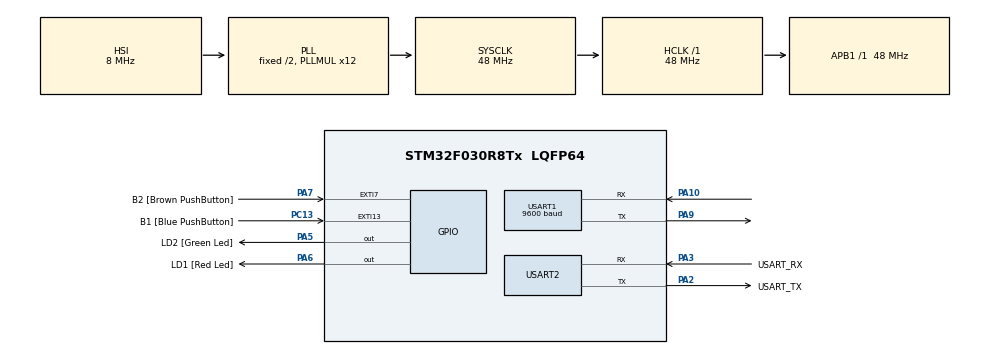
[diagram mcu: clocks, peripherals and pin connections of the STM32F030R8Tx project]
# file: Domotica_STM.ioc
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FREERTOS.INCLUDE_uxTaskGetStackHighWaterMark=1
FREERTOS.Tasks01=defaultTask,0,128,StartDefaultTask,Default,NULL
FREERTOS.configCHECK_FOR_STACK_OVERFLOW=2
Mcu.Family=STM32F0
Mcu.Name=STM32F030R8Tx
Mcu.Package=LQFP64
NVIC.TIM6_IRQn=true\:0\:0\:false\:false\:true\:false\:false
NVIC.TimeBase=TIM6_IRQn
NVIC.TimeBaseIP=TIM6
NVIC.USART1_IRQn=true\:3\:0\:false\:false\:true\:true\:true
PA10.Mode=Asynchronous
PA10.Signal=USART1_RX
PA13.GPIO_Label=TMS
PA13.Mode=Serial_Wire
PA13.Signal=SYS_SWDIO
PA14.GPIO_Label=TCK
PA14.Mode=Serial_Wire
PA14.Signal=SYS_SWCLK
PA2.GPIO_Label=USART_TX
PA2.GPIO_Mode=GPIO_MODE_AF_PP
PA2.GPIO_PuPd=GPIO_NOPULL
PA2.GPIO_Speed=GPIO_SPEED_FREQ_LOW
PA2.Mode=Asynchronous
PA2.Signal=USART2_TX
PA3.GPIO_Label=USART_RX
PA3.GPIO_Mode=GPIO_MODE_AF_PP
PA3.GPIO_PuPd=GPIO_NOPULL
PA3.GPIO_Speed=GPIO_SPEED_FREQ_LOW
PA3.Mode=Asynchronous
PA3.Signal=USART2_RX
PA5.GPIO_Label=LD2 [Green Led]
PA5.GPIO_Mode=GPIO_MODE_OUTPUT_PP
PA5.GPIO_PuPd=GPIO_NOPULL
PA5.GPIO_Speed=GPIO_SPEED_FREQ_LOW
PA5.Signal=GPIO_Output
PA6.GPIO_Label=LD1 [Red Led]
PA6.Signal=GPIO_Output
PA7.GPIO_Label=B2 [Brown PushButton]
PA7.GPIO_ModeDefaultEXTI=GPIO_MODE_IT_RISING
PA7.Signal=GPXTI7
PA9.Mode=Asynchronous
PA9.Signal=USART1_TX
PC13.GPIO_Label=B1 [Blue PushButton]
PC13.GPIO_ModeDefaultEXTI=GPIO_MODE_IT_FALLING
PC13.Signal=GPXTI13
PC14-OSC32_IN.Mode=LSE-External-Oscillator
PC14-OSC32_IN.Signal=RCC_OSC32_IN
PC15-OSC32_OUT.Mode=LSE-External-Oscillator
PC15-OSC32_OUT.Signal=RCC_OSC32_OUT
PF0-OSC_IN.Mode=HSE-External-Clock-Source
PF0-OSC_IN.Signal=RCC_OSC_IN
PF1-OSC_OUT.Signal=RCC_OSC_OUT
ProjectManager.HeapSize=0x200
ProjectManager.StackSize=0x400
ProjectManager.TargetToolchain=SW4STM32
RCC.AHBFreq_Value=48000000
RCC.APB1Freq_Value=48000000
RCC.APB1TimFreq_Value=48000000
RCC.HCLKFreq_Value=48000000
RCC.PLLMUL=RCC_PLL_MUL12
RCC.SYSCLKFreq_VALUE=48000000
RCC.SYSCLKSource=RCC_SYSCLKSOURCE_PLLCLK
USART1.BaudRate=9600
USART1.VirtualMode-Asynchronous=VM_ASYNC
USART2.VirtualMode-Asynchronous=VM_ASYNC
VP_FREERTOS_VS_ENABLE.Mode=Enabled
VP_SYS_VS_tim6.Mode=TIM6
board=NUCLEO-F030R8

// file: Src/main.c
/* USER CODE BEGIN Header */
/**
  ******************************************************************************
  * @file           : main.c
  * @brief          : Main program body
  ******************************************************************************
  * This notice applies to any and all portions of this file
  * that are not between comment pairs USER CODE BEGIN and
  * USER CODE END. Other portions of this file, whether
  * inserted by the user or by software development tools
  * are owned by their respective copyright owners.
  *
  * Copyright (c) 2019 STMicroelectronics International N.V.
  * All rights reserved.
  *
  * Redistribution and use in source and binary forms, with or without
  * modification, are permitted, provided that the following conditions are met:
  *
  * 1. Redistribution of source code must retain the above copyright notice,
  *    this list of conditions and the following disclaimer.
  * 2. Redistributions in binary form must reproduce the above copyright notice,
  *    this list of conditions and the following disclaimer in the documentation
  *    and/or other materials provided with the distribution.
  * 3. Neither the name of STMicroelectronics nor the names of other
  *    contributors to this software may be used to endorse or promote products
  *    derived from this software without specific written permission.
  * 4. This software, including modifications and/or derivative works of this
  *    software, must execute solely and exclusively on microcontroller or
  *    microprocessor devices manufactured by or for STMicroelectronics.
  * 5. Redistribution and use of this software other than as permitted under
  *    this license is void and will automatically terminate your rights under
  *    this license.
  *
  * THIS SOFTWARE IS PROVIDED BY STMICROELECTRONICS AND CONTRIBUTORS "AS IS"
  * AND ANY EXPRESS, IMPLIED OR STATUTORY WARRANTIES, INCLUDING, BUT NOT
  * LIMITED TO, THE IMPLIED WARRANTIES OF MERCHANTABILITY, FITNESS FOR A
  * PARTICULAR PURPOSE AND NON-INFRINGEMENT OF THIRD PARTY INTELLECTUAL PROPERTY
  * RIGHTS ARE DISCLAIMED TO THE FULLEST EXTENT PERMITTED BY LAW. IN NO EVENT
  * SHALL STMICROELECTRONICS OR CONTRIBUTORS BE LIABLE FOR ANY DIRECT, INDIRECT,
  * INCIDENTAL, SPECIAL, EXEMPLARY, OR CONSEQUENTIAL DAMAGES (INCLUDING, BUT NOT
  * LIMITED TO, PROCUREMENT OF SUBSTITUTE GOODS OR SERVICES; LOSS OF USE, DATA,
  * OR PROFITS; OR BUSINESS INTERRUPTION) HOWEVER CAUSED AND ON ANY THEORY OF
  * LIABILITY, WHETHER IN CONTRACT, STRICT LIABILITY, OR TORT (INCLUDING
  * NEGLIGENCE OR OTHERWISE) ARISING IN ANY WAY OUT OF THE USE OF THIS SOFTWARE,
  * EVEN IF ADVISED OF THE POSSIBILITY OF SUCH DAMAGE.
  *
  ******************************************************************************
  */
/* USER CODE END Header */

#include "main.h"
#include "cmsis_os.h"

/* USER CODE BEGIN Includes */
#include "xbee.h"
/* USER CODE END Includes */

osThreadId defaultTaskHandle;
/* USER CODE BEGIN PV */
/* Private variables ---------------------------------------------------------*/

/* USER CODE END PV */

void SystemClock_Config(void);
static void MX_GPIO_Init(void);
static void MX_USART2_UART_Init(void);
static void MX_USART1_UART_Init(void);
void StartDefaultTask(void const * argument);

/* USER CODE BEGIN PFP */
/* Private function prototypes -----------------------------------------------*/
/* USER CODE END PFP */

/* USER CODE BEGIN 0 */
void vApplicationStackOverflowHook( TaskHandle_t xTask, char *pcTaskName )
  {
	  while(1);
  }
/* USER CODE END 0 */

int main(void)
{

  /* MCU Configuration--------------------------------------------------------*/

  /* Reset of all peripherals, Initializes the Flash interface and the Systick. */
  HAL_Init();

  /* Configure the system clock */
  SystemClock_Config();

  /* Initialize all configured peripherals */
  MX_GPIO_Init();
  MX_USART2_UART_Init();
  MX_USART1_UART_Init();
  /* USER CODE BEGIN 2 */

  xTaskCreate( xbeeConfigTask,
		  	  (char *) "XbeeConfig",
			  configMINIMAL_STACK_SIZE,
			  NULL,
			  2,
			  NULL
		  );

  /* USER CODE END 2 */

  /* Create the thread(s) */
  /* definition and creation of defaultTask */
  osThreadDef(defaultTask, StartDefaultTask, osPriorityNormal, 0, 128);
  defaultTaskHandle = osThreadCreate(osThread(defaultTask), NULL);

  /* Start scheduler */
  osKernelStart();

  /* We should never get here as control is now taken by the scheduler */

  /* Infinite loop */
  while (1)
  {

  }
}

void SystemClock_Config(void)
{
  RCC_OscInitTypeDef RCC_OscInitStruct = {0};
  RCC_ClkInitTypeDef RCC_ClkInitStruct = {0};
  RCC_PeriphCLKInitTypeDef PeriphClkInit = {0};

  /**Initializes the CPU, AHB and APB busses clocks
  */
  RCC_OscInitStruct.OscillatorType = RCC_OSCILLATORTYPE_HSI;
  RCC_OscInitStruct.HSIState = RCC_HSI_ON;
  RCC_OscInitStruct.HSICalibrationValue = RCC_HSICALIBRATION_DEFAULT;
  RCC_OscInitStruct.PLL.PLLState = RCC_PLL_ON;
  RCC_OscInitStruct.PLL.PLLSource = RCC_PLLSOURCE_HSI;
  RCC_OscInitStruct.PLL.PLLMUL = RCC_PLL_MUL12;
  RCC_OscInitStruct.PLL.PREDIV = RCC_PREDIV_DIV1;
  if (HAL_RCC_OscConfig(&RCC_OscInitStruct) != HAL_OK)
  {
    Error_Handler();
  }
  /**Initializes the CPU, AHB and APB busses clocks
  */
  RCC_ClkInitStruct.ClockType = RCC_CLOCKTYPE_HCLK|RCC_CLOCKTYPE_SYSCLK
                              |RCC_CLOCKTYPE_PCLK1;
  RCC_ClkInitStruct.SYSCLKSource = RCC_SYSCLKSOURCE_PLLCLK;
  RCC_ClkInitStruct.AHBCLKDivider = RCC_SYSCLK_DIV1;
  RCC_ClkInitStruct.APB1CLKDivider = RCC_HCLK_DIV1;

  if (HAL_RCC_ClockConfig(&RCC_ClkInitStruct, FLASH_LATENCY_1) != HAL_OK)
  {
    Error_Handler();
  }
  PeriphClkInit.PeriphClockSelection = RCC_PERIPHCLK_USART1;
  PeriphClkInit.Usart1ClockSelection = RCC_USART1CLKSOURCE_PCLK1;
  if (HAL_RCCEx_PeriphCLKConfig(&PeriphClkInit) != HAL_OK)
  {
    Error_Handler();
  }
}

static void MX_USART1_UART_Init(void)
{

  LL_USART_InitTypeDef USART_InitStruct = {0};

  LL_GPIO_InitTypeDef GPIO_InitStruct = {0};

  /* Peripheral clock enable */
  LL_APB1_GRP2_EnableClock(LL_APB1_GRP2_PERIPH_USART1);

  LL_AHB1_GRP1_EnableClock(LL_AHB1_GRP1_PERIPH_GPIOA);
  /**USART1 GPIO Configuration
  PA9   ------> USART1_TX
  PA10   ------> USART1_RX
  */
  GPIO_InitStruct.Pin = LL_GPIO_PIN_9;
  GPIO_InitStruct.Mode = LL_GPIO_MODE_ALTERNATE;
  GPIO_InitStruct.Speed = LL_GPIO_SPEED_FREQ_HIGH;
  GPIO_InitStruct.OutputType = LL_GPIO_OUTPUT_PUSHPULL;
  GPIO_InitStruct.Pull = LL_GPIO_PULL_NO;
  GPIO_InitStruct.Alternate = LL_GPIO_AF_1;
  LL_GPIO_Init(GPIOA, &GPIO_InitStruct);

  GPIO_InitStruct.Pin = LL_GPIO_PIN_10;
  GPIO_InitStruct.Mode = LL_GPIO_MODE_ALTERNATE;
  GPIO_InitStruct.Speed = LL_GPIO_SPEED_FREQ_HIGH;
  GPIO_InitStruct.OutputType = LL_GPIO_OUTPUT_PUSHPULL;
  GPIO_InitStruct.Pull = LL_GPIO_PULL_NO;
  GPIO_InitStruct.Alternate = LL_GPIO_AF_1;
  LL_GPIO_Init(GPIOA, &GPIO_InitStruct);

  /* USART1 interrupt Init */
  NVIC_SetPriority(USART1_IRQn, 3);
  NVIC_EnableIRQ(USART1_IRQn);

  USART_InitStruct.BaudRate = 9600;
  USART_InitStruct.DataWidth = LL_USART_DATAWIDTH_8B;
  USART_InitStruct.StopBits = LL_USART_STOPBITS_1;
  USART_InitStruct.Parity = LL_USART_PARITY_NONE;
  USART_InitStruct.TransferDirection = LL_USART_DIRECTION_TX_RX;
  USART_InitStruct.HardwareFlowControl = LL_USART_HWCONTROL_NONE;
  USART_InitStruct.OverSampling = LL_USART_OVERSAMPLING_16;
  LL_USART_Init(USART1, &USART_InitStruct);
  LL_USART_DisableIT_CTS(USART1);
  LL_USART_DisableOverrunDetect(USART1);
  LL_USART_ConfigAsyncMode(USART1);
  LL_USART_Enable(USART1);

}

static void MX_USART2_UART_Init(void)
{

  LL_USART_InitTypeDef USART_InitStruct = {0};

  LL_GPIO_InitTypeDef GPIO_InitStruct = {0};

  /* Peripheral clock enable */
  LL_APB1_GRP1_EnableClock(LL_APB1_GRP1_PERIPH_USART2);

  LL_AHB1_GRP1_EnableClock(LL_AHB1_GRP1_PERIPH_GPIOA);
  /**USART2 GPIO Configuration
  PA2   ------> USART2_TX
  PA3   ------> USART2_RX
  */
  GPIO_InitStruct.Pin = LL_GPIO_PIN_2;
  GPIO_InitStruct.Mode = LL_GPIO_MODE_ALTERNATE;
  GPIO_InitStruct.Speed = LL_GPIO_SPEED_FREQ_LOW;
  GPIO_InitStruct.OutputType = LL_GPIO_OUTPUT_PUSHPULL;
  GPIO_InitStruct.Pull = LL_GPIO_PULL_NO;
  GPIO_InitStruct.Alternate = LL_GPIO_AF_1;
  LL_GPIO_Init(GPIOA, &GPIO_InitStruct);

  GPIO_InitStruct.Pin = LL_GPIO_PIN_3;
  GPIO_InitStruct.Mode = LL_GPIO_MODE_ALTERNATE;
  GPIO_InitStruct.Speed = LL_GPIO_SPEED_FREQ_LOW;
  GPIO_InitStruct.OutputType = LL_GPIO_OUTPUT_PUSHPULL;
  GPIO_InitStruct.Pull = LL_GPIO_PULL_NO;
  GPIO_InitStruct.Alternate = LL_GPIO_AF_1;
  LL_GPIO_Init(GPIOA, &GPIO_InitStruct);

  USART_InitStruct.BaudRate = 38400;
  USART_InitStruct.DataWidth = LL_USART_DATAWIDTH_8B;
  USART_InitStruct.StopBits = LL_USART_STOPBITS_1;
  USART_InitStruct.Parity = LL_USART_PARITY_NONE;
  USART_InitStruct.TransferDirection = LL_USART_DIRECTION_TX_RX;
  USART_InitStruct.HardwareFlowControl = LL_USART_HWCONTROL_NONE;
  USART_InitStruct.OverSampling = LL_USART_OVERSAMPLING_16;
  LL_USART_Init(USART2, &USART_InitStruct);
  LL_USART_DisableIT_CTS(USART2);
  LL_USART_DisableOverrunDetect(USART2);
  LL_USART_ConfigAsyncMode(USART2);
  LL_USART_Enable(USART2);

}

static void MX_GPIO_Init(void)
{
  GPIO_InitTypeDef GPIO_InitStruct = {0};

  /* GPIO Ports Clock Enable */
  __HAL_RCC_GPIOC_CLK_ENABLE();
  __HAL_RCC_GPIOF_CLK_ENABLE();
  __HAL_RCC_GPIOA_CLK_ENABLE();
  __HAL_RCC_GPIOB_CLK_ENABLE();
  __HAL_RCC_GPIOD_CLK_ENABLE();

  /*Configure GPIO pin Output Level */
  HAL_GPIO_WritePin(GPIOA, LD2_Pin|LD1_Pin, GPIO_PIN_RESET);

  /*Configure GPIO pin : B1_Pin */
  GPIO_InitStruct.Pin = B1_Pin;
  GPIO_InitStruct.Mode = GPIO_MODE_IT_FALLING;
  GPIO_InitStruct.Pull = GPIO_NOPULL;
  HAL_GPIO_Init(B1_GPIO_Port, &GPIO_InitStruct);

  /*Configure GPIO pins : PC0 PC1 PC2 PC3
                           PC4 PC5 PC6 PC7
                           PC8 PC9 PC10 PC11
                           PC12 */
  GPIO_InitStruct.Pin = GPIO_PIN_0|GPIO_PIN_1|GPIO_PIN_2|GPIO_PIN_3
                          |GPIO_PIN_4|GPIO_PIN_5|GPIO_PIN_6|GPIO_PIN_7
                          |GPIO_PIN_8|GPIO_PIN_9|GPIO_PIN_10|GPIO_PIN_11
                          |GPIO_PIN_12;
  GPIO_InitStruct.Mode = GPIO_MODE_ANALOG;
  GPIO_InitStruct.Pull = GPIO_NOPULL;
  HAL_GPIO_Init(GPIOC, &GPIO_InitStruct);

  /*Configure GPIO pins : PA0 PA1 PA4 PA8
                           PA11 PA12 PA15 */
  GPIO_InitStruct.Pin = GPIO_PIN_0|GPIO_PIN_1|GPIO_PIN_4|GPIO_PIN_8
                          |GPIO_PIN_11|GPIO_PIN_12|GPIO_PIN_15;
  GPIO_InitStruct.Mode = GPIO_MODE_ANALOG;
  GPIO_InitStruct.Pull = GPIO_NOPULL;
  HAL_GPIO_Init(GPIOA, &GPIO_InitStruct);

  /*Configure GPIO pins : PF4 PF5 PF6 PF7 */
  GPIO_InitStruct.Pin = GPIO_PIN_4|GPIO_PIN_5|GPIO_PIN_6|GPIO_PIN_7;
  GPIO_InitStruct.Mode = GPIO_MODE_ANALOG;
  GPIO_InitStruct.Pull = GPIO_NOPULL;
  HAL_GPIO_Init(GPIOF, &GPIO_InitStruct);

  /*Configure GPIO pins : LD2_Pin LD1_Pin */
  GPIO_InitStruct.Pin = LD2_Pin|LD1_Pin;
  GPIO_InitStruct.Mode = GPIO_MODE_OUTPUT_PP;
  GPIO_InitStruct.Pull = GPIO_NOPULL;
  GPIO_InitStruct.Speed = GPIO_SPEED_FREQ_LOW;
  HAL_GPIO_Init(GPIOA, &GPIO_InitStruct);

  /*Configure GPIO pin : B2_Pin */
  GPIO_InitStruct.Pin = B2_Pin;
  GPIO_InitStruct.Mode = GPIO_MODE_IT_RISING;
  GPIO_InitStruct.Pull = GPIO_NOPULL;
  HAL_GPIO_Init(B2_GPIO_Port, &GPIO_InitStruct);

  /*Configure GPIO pins : PB0 PB1 PB2 PB10
                           PB11 PB12 PB13 PB14
                           PB15 PB3 PB4 PB5
                           PB6 PB7 PB8 PB9 */
  GPIO_InitStruct.Pin = GPIO_PIN_0|GPIO_PIN_1|GPIO_PIN_2|GPIO_PIN_10
                          |GPIO_PIN_11|GPIO_PIN_12|GPIO_PIN_13|GPIO_PIN_14
                          |GPIO_PIN_15|GPIO_PIN_3|GPIO_PIN_4|GPIO_PIN_5
                          |GPIO_PIN_6|GPIO_PIN_7|GPIO_PIN_8|GPIO_PIN_9;
  GPIO_InitStruct.Mode = GPIO_MODE_ANALOG;
  GPIO_InitStruct.Pull = GPIO_NOPULL;
  HAL_GPIO_Init(GPIOB, &GPIO_InitStruct);

  /*Configure GPIO pin : PD2 */
  GPIO_InitStruct.Pin = GPIO_PIN_2;
  GPIO_InitStruct.Mode = GPIO_MODE_ANALOG;
  GPIO_InitStruct.Pull = GPIO_NOPULL;
  HAL_GPIO_Init(GPIOD, &GPIO_InitStruct);

}

void StartDefaultTask(void const * argument)
{

  for(;;)
  {
    osDelay(1);
  }
}

void HAL_TIM_PeriodElapsedCallback(TIM_HandleTypeDef *htim)
{
  if (htim->Instance == TIM6) {
    HAL_IncTick();
  }
}

void Error_Handler(void)
{
  while(1)
  {
  }
}

/************************ (C) COPYRIGHT STMicroelectronics *****END OF FILE****/

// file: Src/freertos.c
/* USER CODE BEGIN Header */
/**
  ******************************************************************************
  * File Name          : freertos.c
  * Description        : Code for freertos applications
  ******************************************************************************
  * This notice applies to any and all portions of this file
  * that are not between comment pairs USER CODE BEGIN and
  * USER CODE END. Other portions of this file, whether
  * inserted by the user or by software development tools
  * are owned by their respective copyright owners.
  *
  * Copyright (c) 2019 STMicroelectronics International N.V.
  * All rights reserved.
  *
  * Redistribution and use in source and binary forms, with or without
  * modification, are permitted, provided that the following conditions are met:
  *
  * 1. Redistribution of source code must retain the above copyright notice,
  *    this list of conditions and the following disclaimer.
  * 2. Redistributions in binary form must reproduce the above copyright notice,
  *    this list of conditions and the following disclaimer in the documentation
  *    and/or other materials provided with the distribution.
  * 3. Neither the name of STMicroelectronics nor the names of other
  *    contributors to this software may be used to endorse or promote products
  *    derived from this software without specific written permission.
  * 4. This software, including modifications and/or derivative works of this
  *    software, must execute solely and exclusively on microcontroller or
  *    microprocessor devices manufactured by or for STMicroelectronics.
  * 5. Redistribution and use of this software other than as permitted under
  *    this license is void and will automatically terminate your rights under
  *    this license.
  *
  * THIS SOFTWARE IS PROVIDED BY STMICROELECTRONICS AND CONTRIBUTORS "AS IS"
  * AND ANY EXPRESS, IMPLIED OR STATUTORY WARRANTIES, INCLUDING, BUT NOT
  * LIMITED TO, THE IMPLIED WARRANTIES OF MERCHANTABILITY, FITNESS FOR A
  * PARTICULAR PURPOSE AND NON-INFRINGEMENT OF THIRD PARTY INTELLECTUAL PROPERTY
  * RIGHTS ARE DISCLAIMED TO THE FULLEST EXTENT PERMITTED BY LAW. IN NO EVENT
  * SHALL STMICROELECTRONICS OR CONTRIBUTORS BE LIABLE FOR ANY DIRECT, INDIRECT,
  * INCIDENTAL, SPECIAL, EXEMPLARY, OR CONSEQUENTIAL DAMAGES (INCLUDING, BUT NOT
  * LIMITED TO, PROCUREMENT OF SUBSTITUTE GOODS OR SERVICES; LOSS OF USE, DATA,
  * OR PROFITS; OR BUSINESS INTERRUPTION) HOWEVER CAUSED AND ON ANY THEORY OF
  * LIABILITY, WHETHER IN CONTRACT, STRICT LIABILITY, OR TORT (INCLUDING
  * NEGLIGENCE OR OTHERWISE) ARISING IN ANY WAY OUT OF THE USE OF THIS SOFTWARE,
  * EVEN IF ADVISED OF THE POSSIBILITY OF SUCH DAMAGE.
  *
  ******************************************************************************
  */
/* USER CODE END Header */

#include "FreeRTOS.h"
#include "task.h"
#include "main.h"

/* Hook prototypes */
void vApplicationStackOverflowHook(xTaskHandle xTask, signed char *pcTaskName);

/* USER CODE BEGIN 4 */
__weak void vApplicationStackOverflowHook(xTaskHandle xTask, signed char *pcTaskName)
{
   /* Run time stack overflow checking is performed if
   configCHECK_FOR_STACK_OVERFLOW is defined to 1 or 2. This hook function is
   called if a stack overflow is detected. */
}
/* USER CODE END 4 */

/************************ (C) COPYRIGHT STMicroelectronics *****END OF FILE****/
